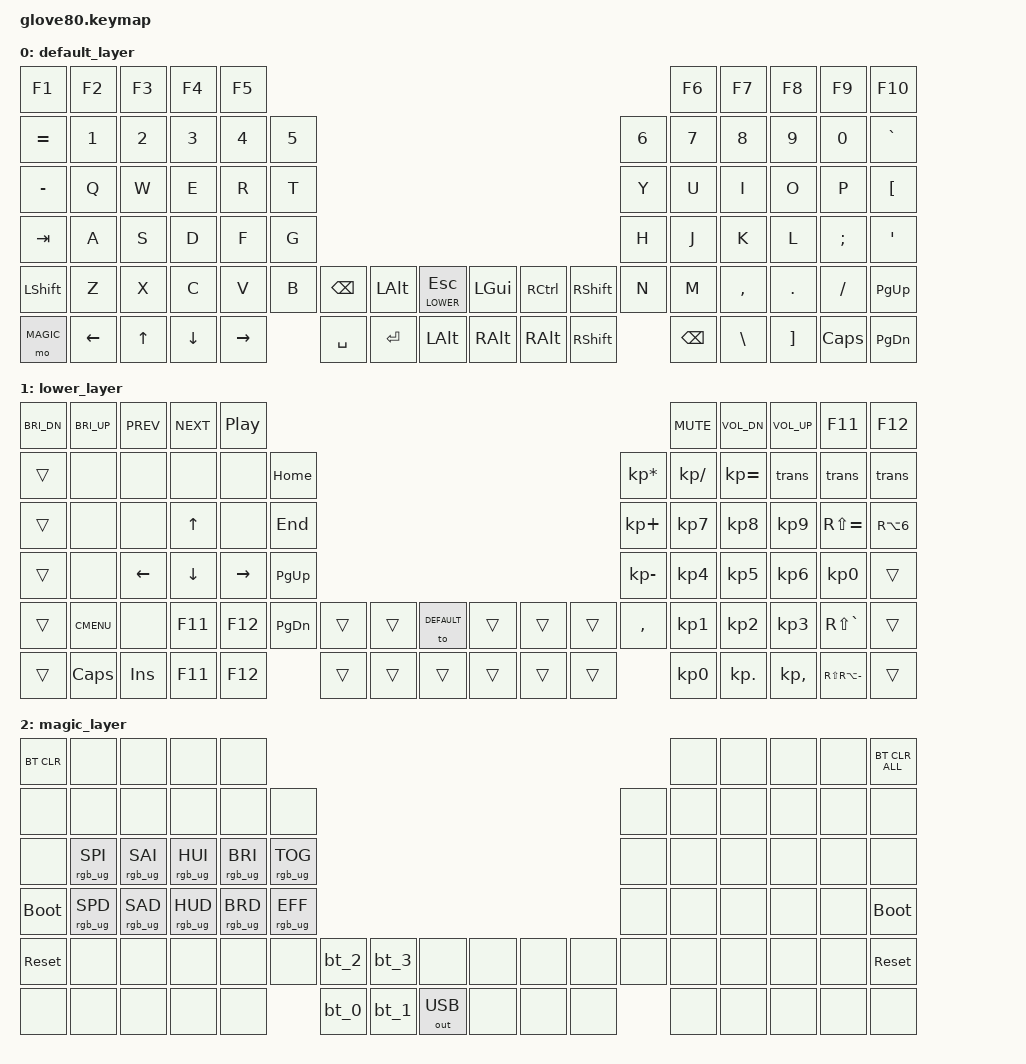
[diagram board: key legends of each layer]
/*
 * Copyright (c) 2020 The ZMK Contributors
 *
 * SPDX-License-Identifier: MIT
 */

#include <behaviors.dtsi>
#include <dt-bindings/zmk/keys.h>
#include <dt-bindings/zmk/bt.h>
#include <dt-bindings/zmk/ext_power.h>
#include <dt-bindings/zmk/outputs.h>
#include <dt-bindings/zmk/rgb.h>

// layers
#define DEFAULT 0
#define LOWER 1
#define MAGIC 2

/ {
    behaviors {
        // For the "layer" key, it'd nice to be able to use it as either a shift or a toggle.
        // Configure it as a tap dance, so the first tap (or hold) is a &mo and the second tap is a &to
        layer_td: tap_dance_0 {
            compatible = "zmk,behavior-tap-dance";
            #binding-cells = <0>;
            tapping-term-ms = <200>;
            bindings = <&mo LOWER>, <&to LOWER>;
        };
    };

    macros {
        bt_0: bt_profile_macro_0 {
            compatible = "zmk,behavior-macro";
            #binding-cells = <0>;
            bindings
                = <&out OUT_BLE>,
                  <&bt BT_SEL 0>;
        };

        bt_1: bt_profile_macro_1 {
            compatible = "zmk,behavior-macro";
            #binding-cells = <0>;
            bindings
                = <&out OUT_BLE>,
                  <&bt BT_SEL 1>;
        };

        bt_2: bt_profile_macro_2 {
            compatible = "zmk,behavior-macro";
            #binding-cells = <0>;
            bindings
                = <&out OUT_BLE>,
                  <&bt BT_SEL 2>;
        };

        bt_3: bt_profile_macro_3 {
            compatible = "zmk,behavior-macro";
            #binding-cells = <0>;
            bindings
                = <&out OUT_BLE>,
                  <&bt BT_SEL 3>;
        };
    };

    keymap {
        compatible = "zmk,keymap";

        default_layer {
            // -----------------------------------------------------------------------------------------------------------------------------------------
            // |  F1   |  F2 |  F3 |  F4  |  F5  |                                                               |  F6   |  F7   |  F8  |   F9  |  F10 |
            // |  =    |  1  |  2  |  3   |  4   |  5   |                                                 |  6   |   7   |   8   |  9   |   0   |   `  |
            // |  -    |  Q  |  W  |  E   |  R   |  T   |                                                 |  Y   |   U   |   I   |  O   |   P   |   [  |
            // |  TAB  |  A  |  S  |  D   |  F   |  G   |                                                 |  H   |   J   |   K   |  L   |   ;   |   '  |
            // | LSHFT |  Z  |  X  |  C   |  V   |  B   | BSPC  | LALT  | ESC   | | LGUI  | RCTRL | RSHFT |  N   |   M   |   ,   |  .   |   /   | PGUP |
            // | MAGIC |  ←  |  ↑  |  ↓   |  →   |      | SPACE | RET   | LALT  | | RALT  | RALT  | RSHFT |      |  BSPC |   \   |  ]   | CAPS  | PGDN |

            bindings = <
            &kp F1        &kp F2           &kp F3           &kp F4           &kp F5                                                                                                                 &kp F6        &kp F7        &kp F8         &kp F9             &kp F10
            &kp EQUAL     &kp N1           &kp N2           &kp N3           &kp N4           &kp N5                                                                               &kp N6           &kp N7        &kp N8        &kp N9         &kp N0             &kp GRAVE
            &kp MINUS     &kp Q            &kp W            &kp E            &kp R            &kp T                                                                                &kp Y            &kp U         &kp I         &kp O          &kp P              &kp LBKT
            &kp TAB       &kp A            &kp S            &kp D            &kp F            &kp G                                                                                &kp H            &kp J         &kp K         &kp L          &kp SEMI           &kp SQT
            &kp LSHFT     &kp Z            &kp X            &kp C            &kp V            &kp B            &kp BSPC   &kp LALT  &lt LOWER ESC  &kp LGUI  &kp RCTRL  &kp RSHFT  &kp N            &kp M         &kp COMMA     &kp DOT        &kp FSLH           &kp PG_UP
            &mo MAGIC     &kp LEFT         &kp UP           &kp DOWN         &kp RIGHT                         &kp SPACE  &kp RET   &kp LALT       &kp RALT  &kp RALT   &kp RSHFT                   &kp BSPC      &kp BSLH      &kp RBKT       &kp CAPS           &kp PG_DN
            >;
        };

        lower_layer {
            bindings = <
            &kp C_BRI_DN  &kp C_BRI_UP     &kp C_PREV       &kp C_NEXT       &kp C_PP                                                                                                             &kp C_MUTE    &kp C_VOL_DN  &kp C_VOL_UP   &kp F11            &kp F12
            &trans        &none            &none            &none            &none            &kp HOME                                   666                                     &kp KP_MULTIPLY  &kp KP_SLASH  &kp KP_EQUAL  &kp trans      &kp trans          &kp trans
            &trans        &none            &none            &kp UP           &none            &kp END                                                                            &kp KP_PLUS      &kp KP_N7     &kp KP_N8     &kp KP_N9      &kp RS(EQUAL)      &kp RA(N6)
            &trans        &none            &kp LEFT         &kp DOWN         &kp RIGHT        &kp PG_UP                                                                          &kp KP_MINUS     &kp KP_N4     &kp KP_N5     &kp KP_N6      &kp KP_N0          &trans
            &trans        &kp K_CMENU      &none            &kp F11          &kp F12          &kp PG_DN        &trans     &trans    &to DEFAULT    &trans    &trans     &trans   &kp COMMA        &kp KP_N1     &kp KP_N2     &kp KP_N3      &kp RS(GRAVE)      &trans
            &trans        &kp CAPS         &kp INS          &kp F11          &kp F12                           &trans     &trans    &trans         &trans    &trans     &trans                    &kp KP_N0     &kp KP_DOT    &kp KP_COMMA   &kp RS(RA(MINUS))  &trans
            >;
        };

        magic_layer {
            bindings = <
            &bt BT_CLR    &none            &none            &none            &none                                                                                                                  &none         &none         &none          &none              &bt BT_CLR_ALL
            &none         &none            &none            &none            &none            &none                                                                                &none            &none         &none         &none          &none              &none
            &none         &rgb_ug RGB_SPI  &rgb_ug RGB_SAI  &rgb_ug RGB_HUI  &rgb_ug RGB_BRI  &rgb_ug RGB_TOG                                                                      &none            &none         &none         &none          &none              &none
            &bootloader   &rgb_ug RGB_SPD  &rgb_ug RGB_SAD  &rgb_ug RGB_HUD  &rgb_ug RGB_BRD  &rgb_ug RGB_EFF                                                                      &none            &none         &none         &none          &none              &bootloader
            &sys_reset    &none            &none            &none            &none            &none            &bt_2      &bt_3     &none          &none     &none      &none      &none            &none         &none         &none          &none              &sys_reset
            &none         &none            &none            &none            &none                             &bt_0      &bt_1     &out OUT_USB   &none     &none      &none                       &none         &none         &none          &none              &none
            >;
        };
    };
};
